AUTOSAR XML (schema 4-0-3)
package /ComponentTypes
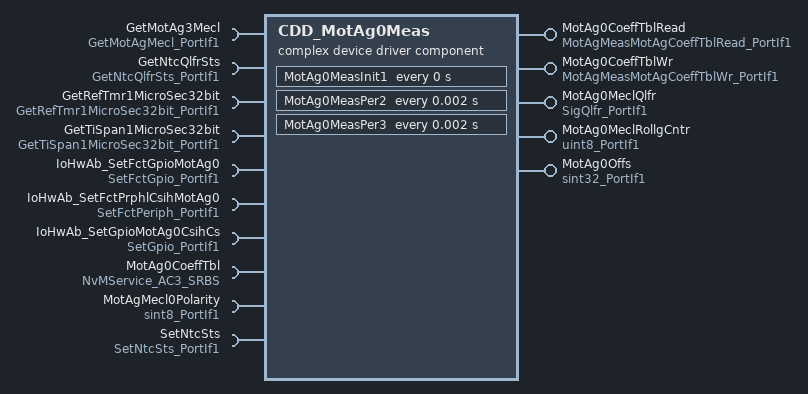
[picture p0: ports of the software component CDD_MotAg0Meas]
  complex device driver sw component type CDD_MotAg0Meas
    5 x provide port:
      MotAg0CoeffTblRead: server-com-spec{operation=Oper, queue-length=1}, provided-interface=MotAgMeasMotAgCoeffTblRead_PortIf1
      MotAg0CoeffTblWr: server-com-spec{operation=Oper, queue-length=1}, provided-interface=MotAgMeasMotAgCoeffTblWr_PortIf1
      MotAg0MeclQlfr: nonqueued-sender-com-spec{data-element=Val, init-value=0}, provided-interface=SigQlfr_PortIf1
      MotAg0MeclRollgCntr: nonqueued-sender-com-spec{data-element=Val, init-value=0}, provided-interface=uint8_PortIf1
      MotAg0Offs: nonqueued-sender-com-spec{data-element=Val, init-value=0}, provided-interface=sint32_PortIf1
    10 x require port:
      GetMotAg3Mecl: required-interface=GetMotAgMecl_PortIf1
      GetNtcQlfrSts: required-interface=GetNtcQlfrSts_PortIf1
      GetRefTmr1MicroSec32bit: required-interface=GetRefTmr1MicroSec32bit_PortIf1
      GetTiSpan1MicroSec32bit: required-interface=GetTiSpan1MicroSec32bit_PortIf1
      IoHwAb_SetFctGpioMotAg0: required-interface=SetFctGpio_PortIf1
      IoHwAb_SetFctPrphlCsihMotAg0: required-interface=SetFctPeriph_PortIf1
      IoHwAb_SetGpioMotAg0CsihCs: required-interface=SetGpio_PortIf1
      MotAg0CoeffTbl: required-interface=NvMService_AC3_SRBS
      MotAgMecl0Polarity: nonqueued-receiver-com-spec{data-element=Val, filter=data-filter-type=ALWAYS, init-value=1}, required-interface=sint8_PortIf1
      SetNtcSts: required-interface=SetNtcSts_PortIf1
    behavior CDD_MotAg0Meas_InternalBehavior: data-type-mapping=Nexteer
      ar-typed-per-instance-memorys:
        17 x data, all with sw-calibration-access=READ-ONLY:
          dMotAg0MeasMotAg0Delta: type=u0p16
          dMotAg0MeasMotAg0RawAgReg: type=uint32
          dMotAg0MeasMotAg0RawErrReg: type=uint32
          dMotAg0MeasMotAg0RawReg: type=Ary1D_u32_10
          dMotAg0MeasMotAg0RawTurnCntrReg: type=uint32
          dMotAg0MeasMotAg0RtOffs: type=sint32
          dMotAg0MeasMotAg0SpiCntrAg: type=u0p16
          dMotAg0MeasMotAg0SpiMecl: type=u0p16
          dMotAg0MeasMotAg0TurnCntr: type=float32
          dMotAg0MeasMotCtrlMotAg3Mecl: type=u0p16
          MotAg0CoeffTbl: type=Ary1D_f32_26
          MotAg0CorrnTbl: type=Ary1D_sm5p12_128
          MotAg0Diagc: type=u0p16
          MotAg0InitOffs: type=uint8
          MotAg0PrevOffs: type=sint32
          MotAg0PrevRollgCntr: type=uint8
          MotAg0PrevSpiErrFltCntr: type=uint16
      operation invoked event OIT_MotAg0CoeffTblRead_Oper_MotAg0CoeffTblRead_Oper: start-on-event=MotAg0CoeffTblRead_Oper, operation=MotAg0CoeffTblRead.Oper
      operation invoked event OIT_MotAg0CoeffTblWr_Oper_MotAg0CoeffTblWr_Oper: start-on-event=MotAg0CoeffTblWr_Oper, operation=MotAg0CoeffTblWr.Oper
      timing event MotAg0MeasInit1_InitEvent: start-on-event=MotAg0MeasInit1, period=0
      timing event TMT_MotAg0MeasPer2: start-on-event=MotAg0MeasPer2, period=0.002
      timing event TMT_MotAg0MeasPer3: start-on-event=MotAg0MeasPer3, period=0.002
      explicit-inter-runnable-variables:
        data MotAg0DiagcAg: type=u0p16, init-value=0
        data MotAg0SpiTrsmEna: type=boolean, init-value=0
        data MotAg3Mecl: type=u0p16, init-value=0
      5 x runnable:
        MotAg0CoeffTblRead_Oper
        MotAg0CoeffTblWr_Oper
          sync call SC_MotAg0CoeffTbl_SetRamBlockStatus: operation=MotAg0CoeffTbl.SetRamBlockStatus, timeout=0
        MotAg0MeasInit1
          sync call SC_MotAg0CoeffTbl_GetErrorStatus: operation=MotAg0CoeffTbl.GetErrorStatus, timeout=0
          sync call SC_MotAg0CoeffTbl_GetErrorStatus_1: operation=MotAg0CoeffTbl.GetErrorStatus, timeout=0
        MotAg0MeasPer2
          data-receive-point-by-arguments:
            access REC_MotAgMecl0Polarity_Val: accessed-variable=MotAgMecl0Polarity.Val
          data-send-points:
            access SEND_MotAg0MeclQlfr_Val: accessed-variable=MotAg0MeclQlfr.Val
            access SEND_MotAg0MeclRollgCntr_Val: accessed-variable=MotAg0MeclRollgCntr.Val
            access SEND_MotAg0Offs_Val: accessed-variable=MotAg0Offs.Val
          read-local-variables:
            access READ_MotAg0DiagcAg: accessed-variable=MotAg0DiagcAg
            access READ_MotAg0SpiTrsmEna: accessed-variable=MotAg0SpiTrsmEna
            access READ_MotAg3Mecl: accessed-variable=MotAg3Mecl
          sync call SC_GetNtcQlfrSts_Oper: operation=GetNtcQlfrSts.Oper, timeout=0
          sync call SC_SetNtcSts_Oper: operation=SetNtcSts.Oper, timeout=0
        MotAg0MeasPer3
          6 x sync call, all with timeout=0:
            SC_GetMotAg3Mecl_Oper: operation=GetMotAg3Mecl.Oper
            SC_GetRefTmr1MicroSec32bit_Oper: operation=GetRefTmr1MicroSec32bit.Oper
            SC_GetTiSpan1MicroSec32bit_Oper: operation=GetTiSpan1MicroSec32bit.Oper
            SC_IoHwAb_SetFctGpioMotAg0_Oper: operation=IoHwAb_SetFctGpioMotAg0.Oper
            SC_IoHwAb_SetFctPrphlCsihMotAg0_Oper: operation=IoHwAb_SetFctPrphlCsihMotAg0.Oper
            SC_IoHwAb_SetGpioMotAg0CsihCs_Oper: operation=IoHwAb_SetGpioMotAg0CsihCs.Oper
          written-local-variables:
            access WRITE_MotAg0DiagcAg: accessed-variable=MotAg0DiagcAg
            access WRITE_MotAg0SpiTrsmEna: accessed-variable=MotAg0SpiTrsmEna
            access WRITE_MotAg3Mecl: accessed-variable=MotAg3Mecl
      swc service dependency NvmMotAg0CoeffTbl
        assigned-datas:
          role=ramBlock, used-data-element=MotAg0CoeffTbl
          role=defaultValue, used-parameter-element=MotAg0CoeffTblDft
        assigned-ports:
          port-prototype=MotAg0CoeffTbl, role=NvMService_AC3_SRBS
          port-prototype=MotAg0CoeffTbl, role=NvMService_AC3_SRBS
        service-needs:
          nv block needs NvmMotAg0CoeffTbl: n-data-sets=0, readonly=false, reliability=ERROR-DETECTION, resistant-to-changed-sw=true, restore-at-start=true, store-at-shutdown=true, write-only-once=false, writing-frequency=0, writing-priority=LOW
      shared-parameters:
        parameter data prototype MotAg0CoeffTblDft: sw-calibration-access=READ-WRITE, type=Ary1D_f32_26, init-value=26 x 0
  swc implementation CDD_MotAg0Meas_Implementation: behavior=CDD_MotAg0Meas_InternalBehavior
    code-descriptors:
      code Default: artifact-descriptors=autosar-engineering-object={short-label=Default, category=SWSRC}
